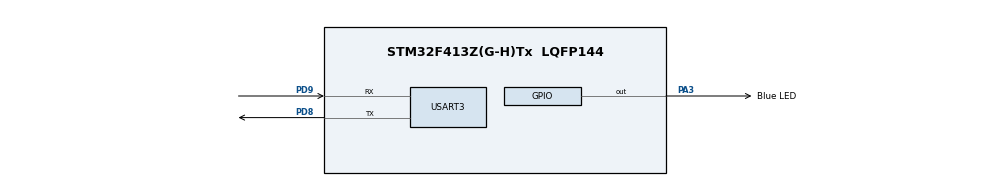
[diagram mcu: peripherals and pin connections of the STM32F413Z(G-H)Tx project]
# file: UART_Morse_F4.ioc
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Dma.Request0=USART3_RX
Dma.Request1=USART3_TX
Dma.USART3_RX.0.Direction=DMA_PERIPH_TO_MEMORY
Dma.USART3_RX.0.FIFOMode=DMA_FIFOMODE_DISABLE
Dma.USART3_RX.0.Instance=DMA1_Stream1
Dma.USART3_RX.0.MemDataAlignment=DMA_MDATAALIGN_BYTE
Dma.USART3_RX.0.MemInc=DMA_MINC_ENABLE
Dma.USART3_RX.0.Mode=DMA_NORMAL
Dma.USART3_RX.0.PeriphDataAlignment=DMA_PDATAALIGN_BYTE
Dma.USART3_RX.0.PeriphInc=DMA_PINC_DISABLE
Dma.USART3_RX.0.Priority=DMA_PRIORITY_LOW
Dma.USART3_TX.1.Direction=DMA_MEMORY_TO_PERIPH
Dma.USART3_TX.1.FIFOMode=DMA_FIFOMODE_DISABLE
Dma.USART3_TX.1.Instance=DMA1_Stream3
Dma.USART3_TX.1.MemDataAlignment=DMA_MDATAALIGN_BYTE
Dma.USART3_TX.1.MemInc=DMA_MINC_ENABLE
Dma.USART3_TX.1.Mode=DMA_NORMAL
Dma.USART3_TX.1.PeriphDataAlignment=DMA_PDATAALIGN_BYTE
Dma.USART3_TX.1.PeriphInc=DMA_PINC_DISABLE
Dma.USART3_TX.1.Priority=DMA_PRIORITY_LOW
Mcu.Family=STM32F4
Mcu.Name=STM32F413Z(G-H)Tx
Mcu.Package=LQFP144
NVIC.DMA1_Stream1_IRQn=true\:0\:0\:false\:false\:true\:false\:true\:true
NVIC.DMA1_Stream3_IRQn=true\:0\:0\:false\:false\:true\:false\:true\:true
NVIC.PriorityGroup=NVIC_PRIORITYGROUP_4
NVIC.USART3_IRQn=true\:0\:0\:false\:false\:true\:true\:true\:true
PA13.Mode=Serial_Wire
PA13.Signal=SYS_JTMS-SWDIO
PA14.Mode=Serial_Wire
PA14.Signal=SYS_JTCK-SWCLK
PA3.GPIO_Label=Blue LED
PA3.GPIO_PuPd=GPIO_NOPULL
PA3.GPIO_Speed=GPIO_SPEED_FREQ_VERY_HIGH
PA3.Signal=GPIO_Output
PD8.Mode=Asynchronous
PD8.Signal=USART3_TX
PD9.Mode=Asynchronous
PD9.Signal=USART3_RX
ProjectManager.HeapSize=0x200
ProjectManager.StackSize=0x400
ProjectManager.TargetToolchain=STM32CubeIDE
RCC.CortexFreq_Value=16000000
RCC.USBFreq_Value=96000000
RCC.VCOOutputFreq_Value=192000000
USART3.VirtualMode=VM_ASYNC
board=custom

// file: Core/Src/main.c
/* USER CODE BEGIN Header */
/**
  ******************************************************************************
  * @file           : main.c
  * @brief          : Main program body
  ******************************************************************************
  * @attention
  *
  * Copyright (c) 2024 STMicroelectronics.
  * All rights reserved.
  *
  * This software is licensed under terms that can be found in the LICENSE file
  * in the root directory of this software component.
  * If no LICENSE file comes with this software, it is provided AS-IS.
  *
  ******************************************************************************
  */
/* USER CODE END Header */
#include "main.h"

UART_HandleTypeDef huart3;
DMA_HandleTypeDef hdma_usart3_rx;
DMA_HandleTypeDef hdma_usart3_tx;

void SystemClock_Config(void);
static void MX_GPIO_Init(void);
static void MX_DMA_Init(void);
static void MX_USART3_UART_Init(void);

/* USER CODE BEGIN 0 */
	uint8_t buffer [30] = {0};
	uint8_t SOL_msg [] = "\r\n===Mensaje nuevo===\r\n\0";
	int wait_time = 0;
/* USER CODE END 0 */

int main(void)
{

  /* MCU Configuration--------------------------------------------------------*/

  /* Reset of all peripherals, Initializes the Flash interface and the Systick. */
  HAL_Init();

  /* Configure the system clock */
  SystemClock_Config();

  /* Initialize all configured peripherals */
  MX_GPIO_Init();
  MX_DMA_Init();
  MX_USART3_UART_Init();
  /* USER CODE BEGIN 2 */
  HAL_UART_Receive_DMA(&huart3, buffer, sizeof(buffer));
  /* USER CODE END 2 */

  /* Infinite loop */
  while (1)
  {
	  for (int i = 0; i < 30; i++) {
	  		wait_time = 1000;
	  		HAL_GPIO_WritePin(Blue_LED_GPIO_Port, Blue_LED_Pin, GPIO_PIN_RESET);
	  		HAL_Delay(100);
	  		switch (buffer[i]) {
	  			case '-':
	  				wait_time = 3000;
	  			case '.':
	  				HAL_GPIO_WritePin(Blue_LED_GPIO_Port, Blue_LED_Pin, GPIO_PIN_SET);
	  				break;
	  			case '/':
	  				wait_time = 3000;
	  			case ' ':
	  				HAL_GPIO_WritePin(Blue_LED_GPIO_Port, Blue_LED_Pin, GPIO_PIN_RESET);
	  				break;
	  			default:
	  				wait_time = 0;
	  				break;
	  		}
	  		if (wait_time != 0) {
	  			if (i == 0) {
	  				SOL_msg[sizeof(SOL_msg)-1] = buffer[i];
	  				HAL_UART_Transmit_DMA(&huart3, SOL_msg, sizeof(SOL_msg));
	  			}
	  			else {
	  				HAL_UART_Transmit_DMA(&huart3, buffer+i*sizeof(uint8_t), sizeof(buffer[i]));
	  			}
	  		}
	  		HAL_Delay(wait_time);
	  	}
  }
}

void SystemClock_Config(void)
{
  RCC_OscInitTypeDef RCC_OscInitStruct = {0};
  RCC_ClkInitTypeDef RCC_ClkInitStruct = {0};

  /** Configure the main internal regulator output voltage
  */
  __HAL_RCC_PWR_CLK_ENABLE();
  __HAL_PWR_VOLTAGESCALING_CONFIG(PWR_REGULATOR_VOLTAGE_SCALE1);

  /** Initializes the RCC Oscillators according to the specified parameters
  * in the RCC_OscInitTypeDef structure.
  */
  RCC_OscInitStruct.OscillatorType = RCC_OSCILLATORTYPE_HSI;
  RCC_OscInitStruct.HSIState = RCC_HSI_ON;
  RCC_OscInitStruct.HSICalibrationValue = RCC_HSICALIBRATION_DEFAULT;
  RCC_OscInitStruct.PLL.PLLState = RCC_PLL_NONE;
  if (HAL_RCC_OscConfig(&RCC_OscInitStruct) != HAL_OK)
  {
    Error_Handler();
  }

  /** Initializes the CPU, AHB and APB buses clocks
  */
  RCC_ClkInitStruct.ClockType = RCC_CLOCKTYPE_HCLK|RCC_CLOCKTYPE_SYSCLK
                              |RCC_CLOCKTYPE_PCLK1|RCC_CLOCKTYPE_PCLK2;
  RCC_ClkInitStruct.SYSCLKSource = RCC_SYSCLKSOURCE_HSI;
  RCC_ClkInitStruct.AHBCLKDivider = RCC_SYSCLK_DIV1;
  RCC_ClkInitStruct.APB1CLKDivider = RCC_HCLK_DIV1;
  RCC_ClkInitStruct.APB2CLKDivider = RCC_HCLK_DIV1;

  if (HAL_RCC_ClockConfig(&RCC_ClkInitStruct, FLASH_LATENCY_0) != HAL_OK)
  {
    Error_Handler();
  }
}

static void MX_USART3_UART_Init(void)
{

  huart3.Instance = USART3;
  huart3.Init.BaudRate = 115200;
  huart3.Init.WordLength = UART_WORDLENGTH_8B;
  huart3.Init.StopBits = UART_STOPBITS_1;
  huart3.Init.Parity = UART_PARITY_NONE;
  huart3.Init.Mode = UART_MODE_TX_RX;
  huart3.Init.HwFlowCtl = UART_HWCONTROL_NONE;
  huart3.Init.OverSampling = UART_OVERSAMPLING_16;
  if (HAL_UART_Init(&huart3) != HAL_OK)
  {
    Error_Handler();
  }

}

static void MX_DMA_Init(void)
{

  /* DMA controller clock enable */
  __HAL_RCC_DMA1_CLK_ENABLE();

  /* DMA interrupt init */
  /* DMA1_Stream1_IRQn interrupt configuration */
  HAL_NVIC_SetPriority(DMA1_Stream1_IRQn, 0, 0);
  HAL_NVIC_EnableIRQ(DMA1_Stream1_IRQn);
  /* DMA1_Stream3_IRQn interrupt configuration */
  HAL_NVIC_SetPriority(DMA1_Stream3_IRQn, 0, 0);
  HAL_NVIC_EnableIRQ(DMA1_Stream3_IRQn);

}

static void MX_GPIO_Init(void)
{
  GPIO_InitTypeDef GPIO_InitStruct = {0};

  /* GPIO Ports Clock Enable */
  __HAL_RCC_GPIOA_CLK_ENABLE();
  __HAL_RCC_GPIOD_CLK_ENABLE();

  /*Configure GPIO pin Output Level */
  HAL_GPIO_WritePin(Blue_LED_GPIO_Port, Blue_LED_Pin, GPIO_PIN_RESET);

  /*Configure GPIO pin : Blue_LED_Pin */
  GPIO_InitStruct.Pin = Blue_LED_Pin;
  GPIO_InitStruct.Mode = GPIO_MODE_OUTPUT_PP;
  GPIO_InitStruct.Pull = GPIO_NOPULL;
  GPIO_InitStruct.Speed = GPIO_SPEED_FREQ_VERY_HIGH;
  HAL_GPIO_Init(Blue_LED_GPIO_Port, &GPIO_InitStruct);

}

/* USER CODE BEGIN 4 */
void HAL_UART_RxCpltCallback(UART_HandleTypeDef *huart) {
	HAL_UART_Receive_DMA(&huart3, buffer, sizeof(buffer));
}
/* USER CODE END 4 */

void Error_Handler(void)
{
  __disable_irq();
  while (1)
  {
  }
}
